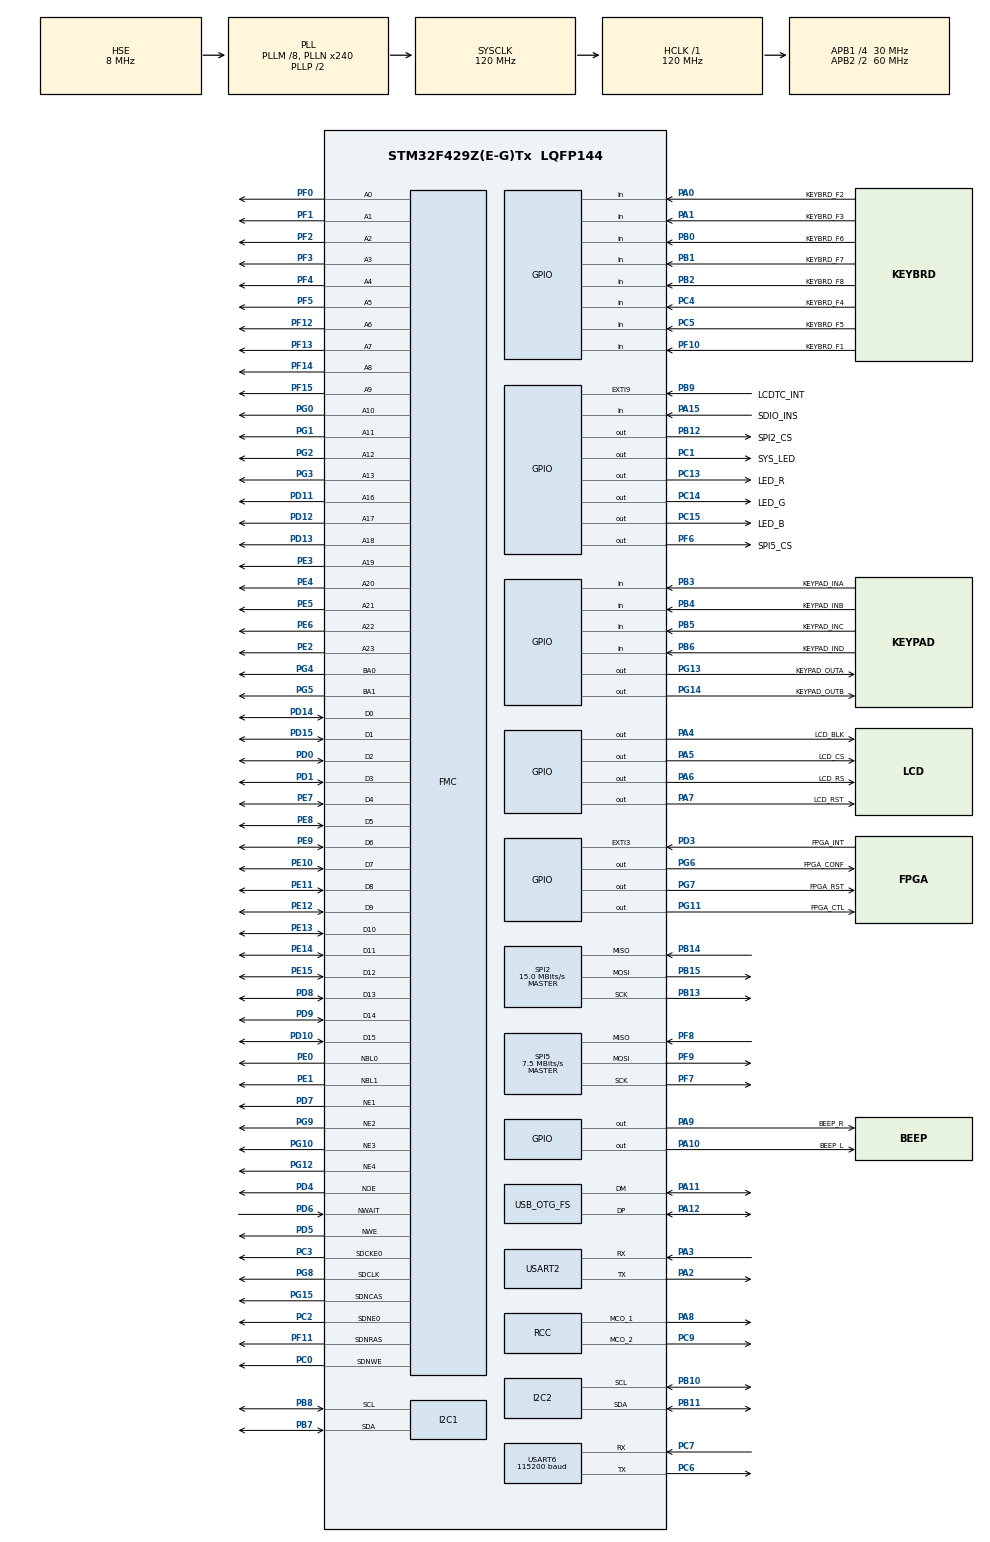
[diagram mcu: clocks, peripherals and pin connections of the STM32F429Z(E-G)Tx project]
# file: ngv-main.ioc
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FATFS._CODE_PAGE=850
FATFS._MAX_SS=4096
FATFS._MIN_SS=4096
FATFS._USE_LFN=1
FMC.AddressSetupTime1=0
FMC.AddressSetupTime2=0
FMC.AddressSetupTime3=0
FMC.AddressSetupTime4=0
FMC.BusTurnAroundDuration1=0
FMC.BusTurnAroundDuration2=0
FMC.BusTurnAroundDuration3=0
FMC.BusTurnAroundDuration4=0
FMC.CASLatency1=FMC_SDRAM_CAS_LATENCY_2
FMC.ColumnBitsNumber1=FMC_SDRAM_COLUMN_BITS_NUM_9
FMC.DataSetupTime1=1
FMC.DataSetupTime2=1
FMC.DataSetupTime3=1
FMC.DataSetupTime4=1
FMC.ExitSelfRefreshDelay1=5
FMC.LoadToActiveDelay1=2
FMC.RCDDelay1=2
FMC.RPDelay1=2
FMC.RPDelay2=2
FMC.ReadPipeDelay1=FMC_SDRAM_RPIPE_DELAY_1
FMC.ReadPipeDelay2=FMC_SDRAM_RPIPE_DELAY_1
FMC.RowCycleDelay1=5
FMC.RowCycleDelay2=5
FMC.SDClockPeriod1=FMC_SDRAM_CLOCK_PERIOD_2
FMC.SDClockPeriod2=FMC_SDRAM_CLOCK_PERIOD_2
FMC.SelfRefreshTime1=4
FMC.WriteRecoveryTime1=2
Mcu.Family=STM32F4
Mcu.Name=STM32F429Z(E-G)Tx
Mcu.Package=LQFP144
NVIC.EXTI3_IRQn=true\:0\:0\:false\:false\:true\:true
NVIC.EXTI9_5_IRQn=true\:0\:0\:false\:false\:true\:true
NVIC.OTG_FS_IRQn=true\:0\:0\:false\:false\:true\:false
NVIC.PriorityGroup=NVIC_PRIORITYGROUP_4
NVIC.TIM1_UP_TIM10_IRQn=true\:0\:0\:false\:false\:true\:true
PA0/WKUP.GPIO_Label=KEYBRD_F2
PA0/WKUP.GPIO_PuPd=GPIO_PULLUP
PA0/WKUP.Signal=GPIO_Input
PA1.GPIO_Label=KEYBRD_F3
PA1.GPIO_Mode=GPIO_MODE_INPUT
PA1.GPIO_PuPd=GPIO_PULLUP
PA1.Signal=GPIO_Input
PA10.GPIO_Label=BEEP_L
PA10.GPIO_Speed=GPIO_SPEED_FREQ_VERY_HIGH
PA10.Signal=GPIO_Output
PA11.Mode=Device_Only
PA11.Signal=USB_OTG_FS_DM
PA12.Mode=Device_Only
PA12.Signal=USB_OTG_FS_DP
PA13.Mode=Serial_Wire
PA13.Signal=SYS_JTMS-SWDIO
PA14.Mode=Serial_Wire
PA14.Signal=SYS_JTCK-SWCLK
PA15.GPIO_Label=SDIO_INS
PA15.GPIO_PuPd=GPIO_PULLUP
PA15.Signal=GPIO_Input
PA2.Mode=Asynchronous
PA2.Signal=USART2_TX
PA3.Mode=Asynchronous
PA3.Signal=USART2_RX
PA4.GPIO_Label=LCD_BLK
PA4.GPIO_Speed=GPIO_SPEED_FREQ_VERY_HIGH
PA4.Signal=GPIO_Output
PA5.GPIO_Label=LCD_CS
PA5.GPIO_Speed=GPIO_SPEED_FREQ_VERY_HIGH
PA5.PinState=GPIO_PIN_SET
PA5.Signal=GPIO_Output
PA6.GPIO_Label=LCD_RS
PA6.GPIO_Speed=GPIO_SPEED_FREQ_VERY_HIGH
PA6.Signal=GPIO_Output
PA7.GPIO_Label=LCD_RST
PA7.GPIO_Speed=GPIO_SPEED_FREQ_VERY_HIGH
PA7.PinState=GPIO_PIN_SET
PA7.Signal=GPIO_Output
PA8.Mode=Clock-out-1
PA8.Signal=RCC_MCO_1
PA9.GPIO_Label=BEEP_R
PA9.GPIO_Speed=GPIO_SPEED_FREQ_VERY_HIGH
PA9.Signal=GPIO_Output
PB0.GPIO_Label=KEYBRD_F6
PB0.GPIO_Mode=GPIO_MODE_INPUT
PB0.GPIO_PuPd=GPIO_PULLUP
PB0.Signal=GPIO_Input
PB1.GPIO_Label=KEYBRD_F7
PB1.GPIO_Mode=GPIO_MODE_INPUT
PB1.GPIO_PuPd=GPIO_PULLUP
PB1.Signal=GPIO_Input
PB10.Mode=I2C
PB10.Signal=I2C2_SCL
PB11.Mode=I2C
PB11.Signal=I2C2_SDA
PB12.GPIO_Label=SPI2_CS
PB12.GPIO_Speed=GPIO_SPEED_FREQ_VERY_HIGH
PB12.PinState=GPIO_PIN_SET
PB12.Signal=GPIO_Output
PB13.Mode=Full_Duplex_Master
PB13.Signal=SPI2_SCK
PB14.Mode=Full_Duplex_Master
PB14.Signal=SPI2_MISO
PB15.Mode=Full_Duplex_Master
PB15.Signal=SPI2_MOSI
PB2/BOOT1.GPIO_Label=KEYBRD_F8
PB2/BOOT1.GPIO_Mode=GPIO_MODE_INPUT
PB2/BOOT1.GPIO_PuPd=GPIO_PULLUP
PB2/BOOT1.Signal=GPIO_Input
PB3.GPIO_Label=KEYPAD_INA
PB3.GPIO_Mode=GPIO_MODE_INPUT
PB3.GPIO_PuPd=GPIO_PULLUP
PB3.Signal=GPIO_Input
PB4.GPIO_Label=KEYPAD_INB
PB4.GPIO_Mode=GPIO_MODE_INPUT
PB4.GPIO_PuPd=GPIO_PULLUP
PB4.Signal=GPIO_Input
PB5.GPIO_Label=KEYPAD_INC
PB5.GPIO_Mode=GPIO_MODE_INPUT
PB5.GPIO_PuPd=GPIO_PULLUP
PB5.Signal=GPIO_Input
PB6.GPIO_Label=KEYPAD_IND
PB6.GPIO_Mode=GPIO_MODE_INPUT
PB6.GPIO_PuPd=GPIO_PULLUP
PB6.Signal=GPIO_Input
PB7.Mode=I2C
PB7.Signal=I2C1_SDA
PB8.Mode=I2C
PB8.Signal=I2C1_SCL
PB9.GPIO_Label=LCDTC_INT
PB9.GPIO_PuPd=GPIO_PULLUP
PB9.Signal=GPXTI9
PC0.Signal=FMC_SDNWE
PC1.GPIO_Label=SYS_LED
PC1.GPIO_Speed=GPIO_SPEED_FREQ_VERY_HIGH
PC1.PinState=GPIO_PIN_SET
PC1.Signal=GPIO_Output
PC10.Signal=SDIO_D2
PC11.Signal=SDIO_D3
PC12.Signal=SDIO_CK
PC13.GPIO_Label=LED_R
PC13.Signal=GPIO_Output
PC14/OSC32_IN.GPIO_Label=LED_G
PC14/OSC32_IN.Signal=GPIO_Output
PC15/OSC32_OUT.GPIO_Label=LED_B
PC15/OSC32_OUT.Signal=GPIO_Output
PC2.Mode=SdramChipSelect1_1
PC2.Signal=FMC_SDNE0
PC3.Mode=SdramChipSelect1_1
PC3.Signal=FMC_SDCKE0
PC4.GPIO_Label=KEYBRD_F4
PC4.GPIO_Mode=GPIO_MODE_INPUT
PC4.GPIO_PuPd=GPIO_PULLUP
PC4.Signal=GPIO_Input
PC5.GPIO_Label=KEYBRD_F5
PC5.GPIO_Mode=GPIO_MODE_INPUT
PC5.GPIO_PuPd=GPIO_PULLUP
PC5.Signal=GPIO_Input
PC6.Mode=Asynchronous
PC6.Signal=USART6_TX
PC7.Mode=Asynchronous
PC7.Signal=USART6_RX
PC8.Signal=SDIO_D0
PC9.Mode=Clock-out-2
PC9.Signal=RCC_MCO_2
PD0.Signal=FMC_D2_DA2
PD1.Signal=FMC_D3_DA3
PD10.Signal=FMC_D15_DA15
PD11.Signal=FMC_A16_CLE
PD12.Signal=FMC_A17_ALE
PD13.Signal=FMC_A18
PD14.Signal=FMC_D0_DA0
PD15.Signal=FMC_D1_DA1
PD2.Signal=SDIO_CMD
PD3.GPIO_Label=FPGA_INT
PD3.GPIO_PuPd=GPIO_PULLUP
PD3.Signal=GPXTI3
PD4.Signal=FMC_NOE
PD5.Signal=FMC_NWE
PD6.Signal=FMC_NWAIT
PD7.Mode=NorPsramChipSelect1_1
PD7.Signal=FMC_NE1
PD8.Signal=FMC_D13_DA13
PD9.Signal=FMC_D14_DA14
PE0.Signal=FMC_NBL0
PE1.Signal=FMC_NBL1
PE10.Signal=FMC_D7_DA7
PE11.Signal=FMC_D8_DA8
PE12.Signal=FMC_D9_DA9
PE13.Signal=FMC_D10_DA10
PE14.Signal=FMC_D11_DA11
PE15.Signal=FMC_D12_DA12
PE2.Signal=FMC_A23
PE3.Signal=FMC_A19
PE4.Signal=FMC_A20
PE5.Signal=FMC_A21
PE6.Signal=FMC_A22
PE7.Signal=FMC_D4_DA4
PE8.Signal=FMC_D5_DA5
PE9.Signal=FMC_D6_DA6
PF0.Signal=FMC_A0
PF1.Signal=FMC_A1
PF10.GPIO_Label=KEYBRD_F1
PF10.GPIO_PuPd=GPIO_PULLUP
PF10.Signal=GPIO_Input
PF11.Signal=FMC_SDNRAS
PF12.Signal=FMC_A6
PF13.Signal=FMC_A7
PF14.Signal=FMC_A8
PF15.Signal=FMC_A9
PF2.Signal=FMC_A2
PF3.Signal=FMC_A3
PF4.Signal=FMC_A4
PF5.Signal=FMC_A5
PF6.GPIO_Label=SPI5_CS
PF6.GPIO_Speed=GPIO_SPEED_FREQ_VERY_HIGH
PF6.PinState=GPIO_PIN_SET
PF6.Signal=GPIO_Output
PF7.Mode=Full_Duplex_Master
PF7.Signal=SPI5_SCK
PF8.Mode=Full_Duplex_Master
PF8.Signal=SPI5_MISO
PF9.Mode=Full_Duplex_Master
PF9.Signal=SPI5_MOSI
PG0.Signal=FMC_A10
PG1.Signal=FMC_A11
PG10.Mode=NorPsramChipSelect3_3
PG10.Signal=FMC_NE3
PG11.GPIO_Label=FPGA_CTL
PG11.GPIO_ModeDefaultOutputPP=GPIO_MODE_OUTPUT_OD
PG11.GPIO_PuPd=GPIO_PULLUP
PG11.GPIO_Speed=GPIO_SPEED_FREQ_VERY_HIGH
PG11.PinState=GPIO_PIN_SET
PG11.Signal=GPIO_Output
PG12.Mode=NorPsramChipSelect4_4
PG12.Signal=FMC_NE4
PG13.GPIO_Label=KEYPAD_OUTA
PG13.GPIO_ModeDefaultOutputPP=GPIO_MODE_OUTPUT_PP
PG13.GPIO_Speed=GPIO_SPEED_FREQ_VERY_HIGH
PG13.PinState=GPIO_PIN_SET
PG13.Signal=GPIO_Output
PG14.GPIO_Label=KEYPAD_OUTB
PG14.GPIO_ModeDefaultOutputPP=GPIO_MODE_OUTPUT_PP
PG14.GPIO_Speed=GPIO_SPEED_FREQ_VERY_HIGH
PG14.PinState=GPIO_PIN_SET
PG14.Signal=GPIO_Output
PG15.Signal=FMC_SDNCAS
PG2.Signal=FMC_A12
PG3.Signal=FMC_A13
PG4.Signal=FMC_A14_BA0
PG5.Signal=FMC_A15_BA1
PG6.GPIO_Label=FPGA_CONF
PG6.GPIO_ModeDefaultOutputPP=GPIO_MODE_OUTPUT_OD
PG6.GPIO_PuPd=GPIO_NOPULL
PG6.GPIO_Speed=GPIO_SPEED_FREQ_VERY_HIGH
PG6.PinState=GPIO_PIN_SET
PG6.Signal=GPIO_Output
PG7.GPIO_Label=FPGA_RST
PG7.GPIO_ModeDefaultOutputPP=GPIO_MODE_OUTPUT_OD
PG7.GPIO_PuPd=GPIO_PULLUP
PG7.GPIO_Speed=GPIO_SPEED_FREQ_VERY_HIGH
PG7.PinState=GPIO_PIN_SET
PG7.Signal=GPIO_Output
PG8.Signal=FMC_SDCLK
PG9.Mode=NorPsramChipSelect2_2
PG9.Signal=FMC_NE2
PH0/OSC_IN.Mode=HSE-External-Oscillator
PH0/OSC_IN.Signal=RCC_OSC_IN
PH1/OSC_OUT.Mode=HSE-External-Oscillator
PH1/OSC_OUT.Signal=RCC_OSC_OUT
ProjectManager.HeapSize=0x1000
ProjectManager.StackSize=0x2000
ProjectManager.TargetToolchain=SW4STM32
RCC.48MHZClocksFreq_Value=48000000
RCC.AHBFreq_Value=120000000
RCC.APB1CLKDivider=RCC_HCLK_DIV4
RCC.APB1Freq_Value=30000000
RCC.APB1TimFreq_Value=60000000
RCC.APB2CLKDivider=RCC_HCLK_DIV2
RCC.APB2Freq_Value=60000000
RCC.APB2TimFreq_Value=120000000
RCC.CortexFreq_Value=120000000
RCC.HCLKFreq_Value=120000000
RCC.HSE_VALUE=8000000
RCC.HSI_VALUE=16000000
RCC.LSE_VALUE=32768
RCC.PLLI2SN=120
RCC.PLLM=8
RCC.PLLN=240
RCC.PLLQ=5
RCC.RCC_MCO1Source=RCC_MCO1SOURCE_PLLCLK
RCC.RCC_MCO2Source=RCC_MCO2SOURCE_PLLI2SCLK
RCC.RCC_MCODiv1=RCC_MCODIV_5
RCC.RCC_MCODiv2=RCC_MCODIV_5
RCC.SYSCLKFreq_VALUE=120000000
RCC.SYSCLKSource=RCC_SYSCLKSOURCE_PLLCLK
RCC.VCOOutputFreq_Value=240000000
SH.FMC_A0.0=FMC_A0,13b-sda1
SH.FMC_A0.1=FMC_A0,24b-a1
SH.FMC_A0.2=FMC_A0,24b-a2
SH.FMC_A0.3=FMC_A0,24b-a3
SH.FMC_A0.4=FMC_A0,24b-a4
SH.FMC_A1.0=FMC_A1,13b-sda1
SH.FMC_A1.1=FMC_A1,24b-a1
SH.FMC_A1.2=FMC_A1,24b-a2
SH.FMC_A1.3=FMC_A1,24b-a3
SH.FMC_A1.4=FMC_A1,24b-a4
SH.FMC_A10.0=FMC_A10,13b-sda1
SH.FMC_A10.1=FMC_A10,24b-a1
SH.FMC_A10.2=FMC_A10,24b-a2
SH.FMC_A10.3=FMC_A10,24b-a3
SH.FMC_A10.4=FMC_A10,24b-a4
SH.FMC_A11.0=FMC_A11,13b-sda1
SH.FMC_A11.1=FMC_A11,24b-a1
SH.FMC_A11.2=FMC_A11,24b-a2
SH.FMC_A11.3=FMC_A11,24b-a3
SH.FMC_A11.4=FMC_A11,24b-a4
SH.FMC_A12.0=FMC_A12,13b-sda1
SH.FMC_A12.1=FMC_A12,24b-a1
SH.FMC_A12.2=FMC_A12,24b-a2
SH.FMC_A12.3=FMC_A12,24b-a3
SH.FMC_A12.4=FMC_A12,24b-a4
SH.FMC_A13.0=FMC_A13,24b-a1
SH.FMC_A13.1=FMC_A13,24b-a2
SH.FMC_A13.2=FMC_A13,24b-a3
SH.FMC_A13.3=FMC_A13,24b-a4
SH.FMC_A14_BA0.0=FMC_BA0,FourSdramBanks1
SH.FMC_A14_BA0.1=FMC_A14,24b-a1
SH.FMC_A14_BA0.2=FMC_A14,24b-a2
SH.FMC_A14_BA0.3=FMC_A14,24b-a3
SH.FMC_A14_BA0.4=FMC_A14,24b-a4
SH.FMC_A15_BA1.0=FMC_BA1,FourSdramBanks1
SH.FMC_A15_BA1.1=FMC_A15,24b-a1
SH.FMC_A15_BA1.2=FMC_A15,24b-a2
SH.FMC_A15_BA1.3=FMC_A15,24b-a3
SH.FMC_A15_BA1.4=FMC_A15,24b-a4
SH.FMC_A16_CLE.0=FMC_A16,24b-a1
SH.FMC_A16_CLE.1=FMC_A16,24b-a2
SH.FMC_A16_CLE.2=FMC_A16,24b-a3
SH.FMC_A16_CLE.3=FMC_A16,24b-a4
SH.FMC_A17_ALE.0=FMC_A17,24b-a1
SH.FMC_A17_ALE.1=FMC_A17,24b-a2
SH.FMC_A17_ALE.2=FMC_A17,24b-a3
SH.FMC_A17_ALE.3=FMC_A17,24b-a4
SH.FMC_A18.0=FMC_A18,24b-a1
SH.FMC_A18.1=FMC_A18,24b-a2
SH.FMC_A18.2=FMC_A18,24b-a3
SH.FMC_A18.3=FMC_A18,24b-a4
SH.FMC_A19.0=FMC_A19,24b-a1
SH.FMC_A19.1=FMC_A19,24b-a2
SH.FMC_A19.2=FMC_A19,24b-a3
SH.FMC_A19.3=FMC_A19,24b-a4
SH.FMC_A2.0=FMC_A2,13b-sda1
SH.FMC_A2.1=FMC_A2,24b-a1
SH.FMC_A2.2=FMC_A2,24b-a2
SH.FMC_A2.3=FMC_A2,24b-a3
SH.FMC_A2.4=FMC_A2,24b-a4
SH.FMC_A20.0=FMC_A20,24b-a1
SH.FMC_A20.1=FMC_A20,24b-a2
SH.FMC_A20.2=FMC_A20,24b-a3
SH.FMC_A20.3=FMC_A20,24b-a4
SH.FMC_A21.0=FMC_A21,24b-a1
SH.FMC_A21.1=FMC_A21,24b-a2
SH.FMC_A21.2=FMC_A21,24b-a3
SH.FMC_A21.3=FMC_A21,24b-a4
SH.FMC_A22.0=FMC_A22,24b-a1
SH.FMC_A22.1=FMC_A22,24b-a2
SH.FMC_A22.2=FMC_A22,24b-a3
SH.FMC_A22.3=FMC_A22,24b-a4
SH.FMC_A23.0=FMC_A23,24b-a1
SH.FMC_A23.1=FMC_A23,24b-a2
SH.FMC_A23.2=FMC_A23,24b-a3
SH.FMC_A23.3=FMC_A23,24b-a4
SH.FMC_A3.0=FMC_A3,13b-sda1
SH.FMC_A3.1=FMC_A3,24b-a1
SH.FMC_A3.2=FMC_A3,24b-a2
SH.FMC_A3.3=FMC_A3,24b-a3
SH.FMC_A3.4=FMC_A3,24b-a4
SH.FMC_A4.0=FMC_A4,13b-sda1
SH.FMC_A4.1=FMC_A4,24b-a1
SH.FMC_A4.2=FMC_A4,24b-a2
SH.FMC_A4.3=FMC_A4,24b-a3
SH.FMC_A4.4=FMC_A4,24b-a4
SH.FMC_A5.0=FMC_A5,13b-sda1
SH.FMC_A5.1=FMC_A5,24b-a1
SH.FMC_A5.2=FMC_A5,24b-a2
SH.FMC_A5.3=FMC_A5,24b-a3
SH.FMC_A5.4=FMC_A5,24b-a4
SH.FMC_A6.0=FMC_A6,13b-sda1
SH.FMC_A6.1=FMC_A6,24b-a1
SH.FMC_A6.2=FMC_A6,24b-a2
SH.FMC_A6.3=FMC_A6,24b-a3
SH.FMC_A6.4=FMC_A6,24b-a4
SH.FMC_A7.0=FMC_A7,13b-sda1
SH.FMC_A7.1=FMC_A7,24b-a1
SH.FMC_A7.2=FMC_A7,24b-a2
SH.FMC_A7.3=FMC_A7,24b-a3
SH.FMC_A7.4=FMC_A7,24b-a4
SH.FMC_A8.0=FMC_A8,13b-sda1
SH.FMC_A8.1=FMC_A8,24b-a1
SH.FMC_A8.2=FMC_A8,24b-a2
SH.FMC_A8.3=FMC_A8,24b-a3
SH.FMC_A8.4=FMC_A8,24b-a4
SH.FMC_A9.0=FMC_A9,13b-sda1
SH.FMC_A9.1=FMC_A9,24b-a1
SH.FMC_A9.2=FMC_A9,24b-a2
SH.FMC_A9.3=FMC_A9,24b-a3
SH.FMC_A9.4=FMC_A9,24b-a4
SH.FMC_D0_DA0.0=FMC_D0,sd-16b-d1
SH.FMC_D0_DA0.1=FMC_D0,8b-d2
SH.FMC_D0_DA0.2=FMC_D0,8b-d3
SH.FMC_D0_DA0.3=FMC_D0,8b-d4
SH.FMC_D0_DA0.4=FMC_D0,8b-d1
SH.FMC_D10_DA10.0=FMC_D10,sd-16b-d1
SH.FMC_D11_DA11.0=FMC_D11,sd-16b-d1
SH.FMC_D12_DA12.0=FMC_D12,sd-16b-d1
SH.FMC_D13_DA13.0=FMC_D13,sd-16b-d1
SH.FMC_D14_DA14.0=FMC_D14,sd-16b-d1
SH.FMC_D15_DA15.0=FMC_D15,sd-16b-d1
SH.FMC_D1_DA1.0=FMC_D1,sd-16b-d1
SH.FMC_D1_DA1.1=FMC_D1,8b-d2
SH.FMC_D1_DA1.2=FMC_D1,8b-d3
SH.FMC_D1_DA1.3=FMC_D1,8b-d4
SH.FMC_D1_DA1.4=FMC_D1,8b-d1
SH.FMC_D2_DA2.0=FMC_D2,sd-16b-d1
SH.FMC_D2_DA2.1=FMC_D2,8b-d2
SH.FMC_D2_DA2.2=FMC_D2,8b-d3
SH.FMC_D2_DA2.3=FMC_D2,8b-d4
SH.FMC_D2_DA2.4=FMC_D2,8b-d1
SH.FMC_D3_DA3.0=FMC_D3,sd-16b-d1
SH.FMC_D3_DA3.1=FMC_D3,8b-d2
SH.FMC_D3_DA3.2=FMC_D3,8b-d3
SH.FMC_D3_DA3.3=FMC_D3,8b-d4
SH.FMC_D3_DA3.4=FMC_D3,8b-d1
SH.FMC_D4_DA4.0=FMC_D4,sd-16b-d1
SH.FMC_D4_DA4.1=FMC_D4,8b-d2
SH.FMC_D4_DA4.2=FMC_D4,8b-d3
SH.FMC_D4_DA4.3=FMC_D4,8b-d4
SH.FMC_D4_DA4.4=FMC_D4,8b-d1
SH.FMC_D5_DA5.0=FMC_D5,sd-16b-d1
SH.FMC_D5_DA5.1=FMC_D5,8b-d2
SH.FMC_D5_DA5.2=FMC_D5,8b-d3
SH.FMC_D5_DA5.3=FMC_D5,8b-d4
SH.FMC_D5_DA5.4=FMC_D5,8b-d1
SH.FMC_D6_DA6.0=FMC_D6,sd-16b-d1
SH.FMC_D6_DA6.1=FMC_D6,8b-d2
SH.FMC_D6_DA6.2=FMC_D6,8b-d3
SH.FMC_D6_DA6.3=FMC_D6,8b-d4
SH.FMC_D6_DA6.4=FMC_D6,8b-d1
SH.FMC_D7_DA7.0=FMC_D7,sd-16b-d1
SH.FMC_D7_DA7.1=FMC_D7,8b-d2
SH.FMC_D7_DA7.2=FMC_D7,8b-d3
SH.FMC_D7_DA7.3=FMC_D7,8b-d4
SH.FMC_D7_DA7.4=FMC_D7,8b-d1
SH.FMC_D8_DA8.0=FMC_D8,sd-16b-d1
SH.FMC_D9_DA9.0=FMC_D9,sd-16b-d1
SH.FMC_NBL0.0=FMC_NBL0,Sd2ByteEnable1
SH.FMC_NBL1.0=FMC_NBL1,Sd2ByteEnable1
SH.FMC_NOE.0=FMC_NOE,Sram1
SH.FMC_NOE.1=FMC_NOE,Sram2
SH.FMC_NOE.2=FMC_NOE,Sram3
SH.FMC_NOE.3=FMC_NOE,Sram4
SH.FMC_NWAIT.0=FMC_NWAIT,AsynchronousWait2
SH.FMC_NWAIT.1=FMC_NWAIT,AsynchronousWait3
SH.FMC_NWAIT.2=FMC_NWAIT,AsynchronousWait4
SH.FMC_NWE.0=FMC_NWE,Sram1
SH.FMC_NWE.1=FMC_NWE,Sram2
SH.FMC_NWE.2=FMC_NWE,Sram3
SH.FMC_NWE.3=FMC_NWE,Sram4
SH.FMC_SDCLK.0=FMC_SDCLK,13b-sda1
SH.FMC_SDNCAS.0=FMC_SDNCAS,13b-sda1
SH.FMC_SDNRAS.0=FMC_SDNRAS,13b-sda1
SH.FMC_SDNWE.0=FMC_SDNWE,13b-sda1
SPI2.BaudRatePrescaler=SPI_BAUDRATEPRESCALER_2
SPI2.CalculateBaudRate=15.0 MBits/s
SPI2.Direction=SPI_DIRECTION_2LINES
SPI2.Mode=SPI_MODE_MASTER
SPI2.VirtualType=VM_MASTER
SPI5.BaudRatePrescaler=SPI_BAUDRATEPRESCALER_8
SPI5.CalculateBaudRate=7.5 MBits/s
SPI5.Direction=SPI_DIRECTION_2LINES
SPI5.Mode=SPI_MODE_MASTER
SPI5.VirtualType=VM_MASTER
TIM10.Period=239
TIM10.Prescaler=5
USART2.VirtualMode=VM_ASYNC
USART6.BaudRate=115200
USART6.VirtualMode=VM_ASYNC
USB_DEVICE.CLASS_NAME_FS=MSC
USB_DEVICE.CONFIGURATION_STRING_MSC_FS=NGV Config
USB_DEVICE.INTERFACE_STRING_MSC_FS=NGV Interface
USB_DEVICE.MANUFACTURER_STRING-MSC_FS=NSDN
USB_DEVICE.MSC_MEDIA_PACKET-MSC_FS=8192
USB_DEVICE.PRODUCT_STRING_MSC_FS=NyaGame Vita v1.0
USB_DEVICE.VirtualMode-MSC_FS=Msc
USB_DEVICE.VirtualModeFS=Msc_FS
USB_OTG_FS.VirtualMode=Device_Only
VP_FATFS_VS_Generic.Mode=User_defined
VP_TIM10_VS_ClockSourceINT.Mode=Enable_Timer
VP_USB_DEVICE_VS_USB_DEVICE_MSC_FS.Mode=MSC_FS
board=ngv-main

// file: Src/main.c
/**
  ******************************************************************************
  * @file           : main.c
  * @brief          : Main program body
  ******************************************************************************
  * This notice applies to any and all portions of this file
  * that are not between comment pairs USER CODE BEGIN and
  * USER CODE END. Other portions of this file, whether
  * inserted by the user or by software development tools
  * are owned by their respective copyright owners.
  *
  * Copyright (c) 2018 STMicroelectronics International N.V.
  * All rights reserved.
  *
  * Redistribution and use in source and binary forms, with or without
  * modification, are permitted, provided that the following conditions are met:
  *
  * 1. Redistribution of source code must retain the above copyright notice,
  *    this list of conditions and the following disclaimer.
  * 2. Redistributions in binary form must reproduce the above copyright notice,
  *    this list of conditions and the following disclaimer in the documentation
  *    and/or other materials provided with the distribution.
  * 3. Neither the name of STMicroelectronics nor the names of other
  *    contributors to this software may be used to endorse or promote products
  *    derived from this software without specific written permission.
  * 4. This software, including modifications and/or derivative works of this
  *    software, must execute solely and exclusively on microcontroller or
  *    microprocessor devices manufactured by or for STMicroelectronics.
  * 5. Redistribution and use of this software other than as permitted under
  *    this license is void and will automatically terminate your rights under
  *    this license.
  *
  * THIS SOFTWARE IS PROVIDED BY STMICROELECTRONICS AND CONTRIBUTORS "AS IS"
  * AND ANY EXPRESS, IMPLIED OR STATUTORY WARRANTIES, INCLUDING, BUT NOT
  * LIMITED TO, THE IMPLIED WARRANTIES OF MERCHANTABILITY, FITNESS FOR A
  * PARTICULAR PURPOSE AND NON-INFRINGEMENT OF THIRD PARTY INTELLECTUAL PROPERTY
  * RIGHTS ARE DISCLAIMED TO THE FULLEST EXTENT PERMITTED BY LAW. IN NO EVENT
  * SHALL STMICROELECTRONICS OR CONTRIBUTORS BE LIABLE FOR ANY DIRECT, INDIRECT,
  * INCIDENTAL, SPECIAL, EXEMPLARY, OR CONSEQUENTIAL DAMAGES (INCLUDING, BUT NOT
  * LIMITED TO, PROCUREMENT OF SUBSTITUTE GOODS OR SERVICES; LOSS OF USE, DATA,
  * OR PROFITS; OR BUSINESS INTERRUPTION) HOWEVER CAUSED AND ON ANY THEORY OF
  * LIABILITY, WHETHER IN CONTRACT, STRICT LIABILITY, OR TORT (INCLUDING
  * NEGLIGENCE OR OTHERWISE) ARISING IN ANY WAY OUT OF THE USE OF THIS SOFTWARE,
  * EVEN IF ADVISED OF THE POSSIBILITY OF SUCH DAMAGE.
  *
  ******************************************************************************
  */
#include "main.h"
#include "stm32f4xx_hal.h"
#include "fatfs.h"
#include "usb_device.h"

/* USER CODE BEGIN Includes */
#include "ngv_bios.h"
#include "ngp_bios.h"
#include "flash.h"
#include "dram.h"
/* USER CODE END Includes */

I2C_HandleTypeDef hi2c1;
I2C_HandleTypeDef hi2c2;

SPI_HandleTypeDef hspi2;
SPI_HandleTypeDef hspi5;

TIM_HandleTypeDef htim10;

UART_HandleTypeDef huart2;
UART_HandleTypeDef huart6;

SRAM_HandleTypeDef hsram1;
SRAM_HandleTypeDef hsram2;
SRAM_HandleTypeDef hsram3;
SRAM_HandleTypeDef hsram4;
SDRAM_HandleTypeDef hsdram1;

/* USER CODE BEGIN PV */
/* Private variables ---------------------------------------------------------*/
extern Flash* flash;
/* USER CODE END PV */

void SystemClock_Config(void);
static void MX_GPIO_Init(void);
static void MX_FMC_Init(void);
static void MX_I2C1_Init(void);
static void MX_SPI2_Init(void);
static void MX_I2C2_Init(void);
static void MX_USART2_UART_Init(void);
static void MX_USART6_UART_Init(void);
static void MX_SPI5_Init(void);
static void MX_TIM10_Init(void);

/* USER CODE BEGIN PFP */
/* Private function prototypes -----------------------------------------------*/
void tick() {
	HAL_GPIO_TogglePin(SYS_LED_GPIO_Port, SYS_LED_Pin);
}

void _lcd_ctl_blk(unsigned char state) {
	HAL_GPIO_WritePin(LCD_BLK_GPIO_Port, LCD_BLK_Pin, state);
}
void _lcd_ctl_cs(unsigned char state) {
	HAL_GPIO_WritePin(LCD_CS_GPIO_Port, LCD_CS_Pin, state);
}
void _lcd_ctl_rs(unsigned char state) {
	HAL_GPIO_WritePin(LCD_RS_GPIO_Port, LCD_RS_Pin, state);
}
void _lcd_ctl_rst(unsigned char state) {
	HAL_GPIO_WritePin(LCD_RST_GPIO_Port, LCD_RST_Pin, state);
}
/* USER CODE END PFP */

int main(void)
{

  /* MCU Configuration----------------------------------------------------------*/

  /* Reset of all peripherals, Initializes the Flash interface and the Systick. */
  HAL_Init();

  /* Configure the system clock */
  SystemClock_Config();

  /* Initialize all configured peripherals */
  MX_GPIO_Init();
  MX_FMC_Init();
  MX_I2C1_Init();
  MX_SPI2_Init();
  MX_I2C2_Init();
  MX_USART2_UART_Init();
  MX_USART6_UART_Init();
  MX_SPI5_Init();
  MX_USB_DEVICE_Init();
  MX_FATFS_Init();
  MX_TIM10_Init();
  /* USER CODE BEGIN 2 */
  SDRAM_Init(&hsdram1);

  flash = FlashInit(&hspi5, SPI5_CS_GPIO_Port, SPI5_CS_Pin, W25Q128);
  ngv_setup();
  /* USER CODE END 2 */

  /* Infinite loop */
  /* USER CODE BEGIN WHILE */
  while (1) ngp_loop();
  /* USER CODE END WHILE */

}

void SystemClock_Config(void)
{

  RCC_OscInitTypeDef RCC_OscInitStruct;
  RCC_ClkInitTypeDef RCC_ClkInitStruct;
  RCC_PeriphCLKInitTypeDef PeriphClkInitStruct;

    /**Configure the main internal regulator output voltage
    */
  __HAL_RCC_PWR_CLK_ENABLE();

  __HAL_PWR_VOLTAGESCALING_CONFIG(PWR_REGULATOR_VOLTAGE_SCALE3);

    /**Initializes the CPU, AHB and APB busses clocks
    */
  RCC_OscInitStruct.OscillatorType = RCC_OSCILLATORTYPE_HSE;
  RCC_OscInitStruct.HSEState = RCC_HSE_ON;
  RCC_OscInitStruct.PLL.PLLState = RCC_PLL_ON;
  RCC_OscInitStruct.PLL.PLLSource = RCC_PLLSOURCE_HSE;
  RCC_OscInitStruct.PLL.PLLM = 8;
  RCC_OscInitStruct.PLL.PLLN = 240;
  RCC_OscInitStruct.PLL.PLLP = RCC_PLLP_DIV2;
  RCC_OscInitStruct.PLL.PLLQ = 5;
  if (HAL_RCC_OscConfig(&RCC_OscInitStruct) != HAL_OK)
  {
    _Error_Handler(__FILE__, __LINE__);
  }

    /**Initializes the CPU, AHB and APB busses clocks
    */
  RCC_ClkInitStruct.ClockType = RCC_CLOCKTYPE_HCLK|RCC_CLOCKTYPE_SYSCLK
                              |RCC_CLOCKTYPE_PCLK1|RCC_CLOCKTYPE_PCLK2;
  RCC_ClkInitStruct.SYSCLKSource = RCC_SYSCLKSOURCE_PLLCLK;
  RCC_ClkInitStruct.AHBCLKDivider = RCC_SYSCLK_DIV1;
  RCC_ClkInitStruct.APB1CLKDivider = RCC_HCLK_DIV4;
  RCC_ClkInitStruct.APB2CLKDivider = RCC_HCLK_DIV2;

  if (HAL_RCC_ClockConfig(&RCC_ClkInitStruct, FLASH_LATENCY_3) != HAL_OK)
  {
    _Error_Handler(__FILE__, __LINE__);
  }

  PeriphClkInitStruct.PeriphClockSelection = RCC_PERIPHCLK_PLLI2S;
  PeriphClkInitStruct.PLLI2S.PLLI2SN = 120;
  PeriphClkInitStruct.PLLI2S.PLLI2SR = 2;
  if (HAL_RCCEx_PeriphCLKConfig(&PeriphClkInitStruct) != HAL_OK)
  {
    _Error_Handler(__FILE__, __LINE__);
  }

  HAL_RCC_MCOConfig(RCC_MCO1, RCC_MCO1SOURCE_PLLCLK, RCC_MCODIV_5);

  HAL_RCC_MCOConfig(RCC_MCO2, RCC_MCO2SOURCE_PLLI2SCLK, RCC_MCODIV_5);

    /**Configure the Systick interrupt time
    */
  HAL_SYSTICK_Config(HAL_RCC_GetHCLKFreq()/1000);

    /**Configure the Systick
    */
  HAL_SYSTICK_CLKSourceConfig(SYSTICK_CLKSOURCE_HCLK);

  /* SysTick_IRQn interrupt configuration */
  HAL_NVIC_SetPriority(SysTick_IRQn, 0, 0);
}

/* I2C1 init function */
static void MX_I2C1_Init(void)
{

  hi2c1.Instance = I2C1;
  hi2c1.Init.ClockSpeed = 100000;
  hi2c1.Init.DutyCycle = I2C_DUTYCYCLE_2;
  hi2c1.Init.OwnAddress1 = 0;
  hi2c1.Init.AddressingMode = I2C_ADDRESSINGMODE_7BIT;
  hi2c1.Init.DualAddressMode = I2C_DUALADDRESS_DISABLE;
  hi2c1.Init.OwnAddress2 = 0;
  hi2c1.Init.GeneralCallMode = I2C_GENERALCALL_DISABLE;
  hi2c1.Init.NoStretchMode = I2C_NOSTRETCH_DISABLE;
  if (HAL_I2C_Init(&hi2c1) != HAL_OK)
  {
    _Error_Handler(__FILE__, __LINE__);
  }

}

/* I2C2 init function */
static void MX_I2C2_Init(void)
{

  hi2c2.Instance = I2C2;
  hi2c2.Init.ClockSpeed = 100000;
  hi2c2.Init.DutyCycle = I2C_DUTYCYCLE_2;
  hi2c2.Init.OwnAddress1 = 0;
  hi2c2.Init.AddressingMode = I2C_ADDRESSINGMODE_7BIT;
  hi2c2.Init.DualAddressMode = I2C_DUALADDRESS_DISABLE;
  hi2c2.Init.OwnAddress2 = 0;
  hi2c2.Init.GeneralCallMode = I2C_GENERALCALL_DISABLE;
  hi2c2.Init.NoStretchMode = I2C_NOSTRETCH_DISABLE;
  if (HAL_I2C_Init(&hi2c2) != HAL_OK)
  {
    _Error_Handler(__FILE__, __LINE__);
  }

}

/* SPI2 init function */
static void MX_SPI2_Init(void)
{

  /* SPI2 parameter configuration*/
  hspi2.Instance = SPI2;
  hspi2.Init.Mode = SPI_MODE_MASTER;
  hspi2.Init.Direction = SPI_DIRECTION_2LINES;
  hspi2.Init.DataSize = SPI_DATASIZE_8BIT;
  hspi2.Init.CLKPolarity = SPI_POLARITY_LOW;
  hspi2.Init.CLKPhase = SPI_PHASE_1EDGE;
  hspi2.Init.NSS = SPI_NSS_SOFT;
  hspi2.Init.BaudRatePrescaler = SPI_BAUDRATEPRESCALER_2;
  hspi2.Init.FirstBit = SPI_FIRSTBIT_MSB;
  hspi2.Init.TIMode = SPI_TIMODE_DISABLE;
  hspi2.Init.CRCCalculation = SPI_CRCCALCULATION_DISABLE;
  hspi2.Init.CRCPolynomial = 10;
  if (HAL_SPI_Init(&hspi2) != HAL_OK)
  {
    _Error_Handler(__FILE__, __LINE__);
  }

}

/* SPI5 init function */
static void MX_SPI5_Init(void)
{

  /* SPI5 parameter configuration*/
  hspi5.Instance = SPI5;
  hspi5.Init.Mode = SPI_MODE_MASTER;
  hspi5.Init.Direction = SPI_DIRECTION_2LINES;
  hspi5.Init.DataSize = SPI_DATASIZE_8BIT;
  hspi5.Init.CLKPolarity = SPI_POLARITY_LOW;
  hspi5.Init.CLKPhase = SPI_PHASE_1EDGE;
  hspi5.Init.NSS = SPI_NSS_SOFT;
  hspi5.Init.BaudRatePrescaler = SPI_BAUDRATEPRESCALER_8;
  hspi5.Init.FirstBit = SPI_FIRSTBIT_MSB;
  hspi5.Init.TIMode = SPI_TIMODE_DISABLE;
  hspi5.Init.CRCCalculation = SPI_CRCCALCULATION_DISABLE;
  hspi5.Init.CRCPolynomial = 10;
  if (HAL_SPI_Init(&hspi5) != HAL_OK)
  {
    _Error_Handler(__FILE__, __LINE__);
  }

}

/* TIM10 init function */
static void MX_TIM10_Init(void)
{

  htim10.Instance = TIM10;
  htim10.Init.Prescaler = 5;
  htim10.Init.CounterMode = TIM_COUNTERMODE_UP;
  htim10.Init.Period = 239;
  htim10.Init.ClockDivision = TIM_CLOCKDIVISION_DIV1;
  if (HAL_TIM_Base_Init(&htim10) != HAL_OK)
  {
    _Error_Handler(__FILE__, __LINE__);
  }

}

/* USART2 init function */
static void MX_USART2_UART_Init(void)
{

  huart2.Instance = USART2;
  huart2.Init.BaudRate = 115200;
  huart2.Init.WordLength = UART_WORDLENGTH_8B;
  huart2.Init.StopBits = UART_STOPBITS_1;
  huart2.Init.Parity = UART_PARITY_NONE;
  huart2.Init.Mode = UART_MODE_TX_RX;
  huart2.Init.HwFlowCtl = UART_HWCONTROL_NONE;
  huart2.Init.OverSampling = UART_OVERSAMPLING_16;
  if (HAL_UART_Init(&huart2) != HAL_OK)
  {
    _Error_Handler(__FILE__, __LINE__);
  }

}

/* USART6 init function */
static void MX_USART6_UART_Init(void)
{

  huart6.Instance = USART6;
  huart6.Init.BaudRate = 115200;
  huart6.Init.WordLength = UART_WORDLENGTH_8B;
  huart6.Init.StopBits = UART_STOPBITS_1;
  huart6.Init.Parity = UART_PARITY_NONE;
  huart6.Init.Mode = UART_MODE_TX_RX;
  huart6.Init.HwFlowCtl = UART_HWCONTROL_NONE;
  huart6.Init.OverSampling = UART_OVERSAMPLING_16;
  if (HAL_UART_Init(&huart6) != HAL_OK)
  {
    _Error_Handler(__FILE__, __LINE__);
  }

}

/* FMC initialization function */
static void MX_FMC_Init(void)
{
  FMC_NORSRAM_TimingTypeDef Timing;
  FMC_SDRAM_TimingTypeDef SdramTiming;

  /** Perform the SRAM1 memory initialization sequence
  */
  hsram1.Instance = FMC_NORSRAM_DEVICE;
  hsram1.Extended = FMC_NORSRAM_EXTENDED_DEVICE;
  /* hsram1.Init */
  hsram1.Init.NSBank = FMC_NORSRAM_BANK1;
  hsram1.Init.DataAddressMux = FMC_DATA_ADDRESS_MUX_DISABLE;
  hsram1.Init.MemoryType = FMC_MEMORY_TYPE_SRAM;
  hsram1.Init.MemoryDataWidth = FMC_NORSRAM_MEM_BUS_WIDTH_8;
  hsram1.Init.BurstAccessMode = FMC_BURST_ACCESS_MODE_DISABLE;
  hsram1.Init.WaitSignalPolarity = FMC_WAIT_SIGNAL_POLARITY_LOW;
  hsram1.Init.WrapMode = FMC_WRAP_MODE_DISABLE;
  hsram1.Init.WaitSignalActive = FMC_WAIT_TIMING_BEFORE_WS;
  hsram1.Init.WriteOperation = FMC_WRITE_OPERATION_DISABLE;
  hsram1.Init.WaitSignal = FMC_WAIT_SIGNAL_DISABLE;
  hsram1.Init.ExtendedMode = FMC_EXTENDED_MODE_DISABLE;
  hsram1.Init.AsynchronousWait = FMC_ASYNCHRONOUS_WAIT_DISABLE;
  hsram1.Init.WriteBurst = FMC_WRITE_BURST_DISABLE;
  hsram1.Init.ContinuousClock = FMC_CONTINUOUS_CLOCK_SYNC_ONLY;
  hsram1.Init.PageSize = FMC_PAGE_SIZE_NONE;
  /* Timing */
  Timing.AddressSetupTime = 0;
  Timing.AddressHoldTime = 15;
  Timing.DataSetupTime = 1;
  Timing.BusTurnAroundDuration = 0;
  Timing.CLKDivision = 16;
  Timing.DataLatency = 17;
  Timing.AccessMode = FMC_ACCESS_MODE_A;
  /* ExtTiming */

  if (HAL_SRAM_Init(&hsram1, &Timing, NULL) != HAL_OK)
  {
    _Error_Handler(__FILE__, __LINE__);
  }

  /** Perform the SRAM2 memory initialization sequence
  */
  hsram2.Instance = FMC_NORSRAM_DEVICE;
  hsram2.Extended = FMC_NORSRAM_EXTENDED_DEVICE;
  /* hsram2.Init */
  hsram2.Init.NSBank = FMC_NORSRAM_BANK2;
  hsram2.Init.DataAddressMux = FMC_DATA_ADDRESS_MUX_DISABLE;
  hsram2.Init.MemoryType = FMC_MEMORY_TYPE_SRAM;
  hsram2.Init.MemoryDataWidth = FMC_NORSRAM_MEM_BUS_WIDTH_8;
  hsram2.Init.BurstAccessMode = FMC_BURST_ACCESS_MODE_DISABLE;
  hsram2.Init.WaitSignalPolarity = FMC_WAIT_SIGNAL_POLARITY_LOW;
  hsram2.Init.WrapMode = FMC_WRAP_MODE_DISABLE;
  hsram2.Init.WaitSignalActive = FMC_WAIT_TIMING_BEFORE_WS;
  hsram2.Init.WriteOperation = FMC_WRITE_OPERATION_DISABLE;
  hsram2.Init.WaitSignal = FMC_WAIT_SIGNAL_DISABLE;
  hsram2.Init.ExtendedMode = FMC_EXTENDED_MODE_DISABLE;
  hsram2.Init.AsynchronousWait = FMC_ASYNCHRONOUS_WAIT_ENABLE;
  hsram2.Init.WriteBurst = FMC_WRITE_BURST_DISABLE;
  hsram2.Init.ContinuousClock = FMC_CONTINUOUS_CLOCK_SYNC_ONLY;
  hsram2.Init.PageSize = FMC_PAGE_SIZE_NONE;
  /* Timing */
  Timing.AddressSetupTime = 0;
  Timing.AddressHoldTime = 15;
  Timing.DataSetupTime = 1;
  Timing.BusTurnAroundDuration = 0;
  Timing.CLKDivision = 16;
  Timing.DataLatency = 17;
  Timing.AccessMode = FMC_ACCESS_MODE_A;
  /* ExtTiming */

  if (HAL_SRAM_Init(&hsram2, &Timing, NULL) != HAL_OK)
  {
    _Error_Handler(__FILE__, __LINE__);
  }

  /** Perform the SRAM3 memory initialization sequence
  */
  hsram3.Instance = FMC_NORSRAM_DEVICE;
  hsram3.Extended = FMC_NORSRAM_EXTENDED_DEVICE;
  /* hsram3.Init */
  hsram3.Init.NSBank = FMC_NORSRAM_BANK3;
  hsram3.Init.DataAddressMux = FMC_DATA_ADDRESS_MUX_DISABLE;
  hsram3.Init.MemoryType = FMC_MEMORY_TYPE_SRAM;
  hsram3.Init.MemoryDataWidth = FMC_NORSRAM_MEM_BUS_WIDTH_8;
  hsram3.Init.BurstAccessMode = FMC_BURST_ACCESS_MODE_DISABLE;
  hsram3.Init.WaitSignalPolarity = FMC_WAIT_SIGNAL_POLARITY_LOW;
  hsram3.Init.WrapMode = FMC_WRAP_MODE_DISABLE;
  hsram3.Init.WaitSignalActive = FMC_WAIT_TIMING_BEFORE_WS;
  hsram3.Init.WriteOperation = FMC_WRITE_OPERATION_DISABLE;
  hsram3.Init.WaitSignal = FMC_WAIT_SIGNAL_DISABLE;
  hsram3.Init.ExtendedMode = FMC_EXTENDED_MODE_DISABLE;
  hsram3.Init.AsynchronousWait = FMC_ASYNCHRONOUS_WAIT_ENABLE;
  hsram3.Init.WriteBurst = FMC_WRITE_BURST_DISABLE;
  hsram3.Init.ContinuousClock = FMC_CONTINUOUS_CLOCK_SYNC_ONLY;
  hsram3.Init.PageSize = FMC_PAGE_SIZE_NONE;
  /* Timing */
  Timing.AddressSetupTime = 0;
  Timing.AddressHoldTime = 15;
  Timing.DataSetupTime = 1;
  Timing.BusTurnAroundDuration = 0;
  Timing.CLKDivision = 16;
  Timing.DataLatency = 17;
  Timing.AccessMode = FMC_ACCESS_MODE_A;
  /* ExtTiming */

  if (HAL_SRAM_Init(&hsram3, &Timing, NULL) != HAL_OK)
  {
    _Error_Handler(__FILE__, __LINE__);
  }

  /** Perform the SRAM4 memory initialization sequence
  */
  hsram4.Instance = FMC_NORSRAM_DEVICE;
  hsram4.Extended = FMC_NORSRAM_EXTENDED_DEVICE;
  /* hsram4.Init */
  hsram4.Init.NSBank = FMC_NORSRAM_BANK4;
  hsram4.Init.DataAddressMux = FMC_DATA_ADDRESS_MUX_DISABLE;
  hsram4.Init.MemoryType = FMC_MEMORY_TYPE_SRAM;
  hsram4.Init.MemoryDataWidth = FMC_NORSRAM_MEM_BUS_WIDTH_8;
  hsram4.Init.BurstAccessMode = FMC_BURST_ACCESS_MODE_DISABLE;
  hsram4.Init.WaitSignalPolarity = FMC_WAIT_SIGNAL_POLARITY_LOW;
  hsram4.Init.WrapMode = FMC_WRAP_MODE_DISABLE;
  hsram4.Init.WaitSignalActive = FMC_WAIT_TIMING_BEFORE_WS;
  hsram4.Init.WriteOperation = FMC_WRITE_OPERATION_DISABLE;
  hsram4.Init.WaitSignal = FMC_WAIT_SIGNAL_DISABLE;
  hsram4.Init.ExtendedMode = FMC_EXTENDED_MODE_DISABLE;
  hsram4.Init.AsynchronousWait = FMC_ASYNCHRONOUS_WAIT_ENABLE;
  hsram4.Init.WriteBurst = FMC_WRITE_BURST_DISABLE;
  hsram4.Init.ContinuousClock = FMC_CONTINUOUS_CLOCK_SYNC_ONLY;
  hsram4.Init.PageSize = FMC_PAGE_SIZE_NONE;
  /* Timing */
  Timing.AddressSetupTime = 0;
  Timing.AddressHoldTime = 15;
  Timing.DataSetupTime = 1;
  Timing.BusTurnAroundDuration = 0;
  Timing.CLKDivision = 16;
  Timing.DataLatency = 17;
  Timing.AccessMode = FMC_ACCESS_MODE_A;
  /* ExtTiming */

  if (HAL_SRAM_Init(&hsram4, &Timing, NULL) != HAL_OK)
  {
    _Error_Handler(__FILE__, __LINE__);
  }

  /** Perform the SDRAM1 memory initialization sequence
  */
  hsdram1.Instance = FMC_SDRAM_DEVICE;
  /* hsdram1.Init */
  hsdram1.Init.SDBank = FMC_SDRAM_BANK1;
  hsdram1.Init.ColumnBitsNumber = FMC_SDRAM_COLUMN_BITS_NUM_9;
  hsdram1.Init.RowBitsNumber = FMC_SDRAM_ROW_BITS_NUM_13;
  hsdram1.Init.MemoryDataWidth = FMC_SDRAM_MEM_BUS_WIDTH_16;
  hsdram1.Init.InternalBankNumber = FMC_SDRAM_INTERN_BANKS_NUM_4;
  hsdram1.Init.CASLatency = FMC_SDRAM_CAS_LATENCY_2;
  hsdram1.Init.WriteProtection = FMC_SDRAM_WRITE_PROTECTION_DISABLE;
  hsdram1.Init.SDClockPeriod = FMC_SDRAM_CLOCK_PERIOD_2;
  hsdram1.Init.ReadBurst = FMC_SDRAM_RBURST_DISABLE;
  hsdram1.Init.ReadPipeDelay = FMC_SDRAM_RPIPE_DELAY_1;
  /* SdramTiming */
  SdramTiming.LoadToActiveDelay = 2;
  SdramTiming.ExitSelfRefreshDelay = 5;
  SdramTiming.SelfRefreshTime = 4;
  SdramTiming.RowCycleDelay = 5;
  SdramTiming.WriteRecoveryTime = 2;
  SdramTiming.RPDelay = 2;
  SdramTiming.RCDDelay = 2;

  if (HAL_SDRAM_Init(&hsdram1, &SdramTiming) != HAL_OK)
  {
    _Error_Handler(__FILE__, __LINE__);
  }

}

/** Configure pins as
        * Analog
        * Input
        * Output
        * EVENT_OUT
        * EXTI
     PC8   ------> SDIO_D0
     PC9   ------> RCC_MCO_2
     PA8   ------> RCC_MCO_1
     PC10   ------> SDIO_D2
     PC11   ------> SDIO_D3
     PC12   ------> SDIO_CK
     PD2   ------> SDIO_CMD
*/
static void MX_GPIO_Init(void)
{

  GPIO_InitTypeDef GPIO_InitStruct;

  /* GPIO Ports Clock Enable */
  __HAL_RCC_GPIOE_CLK_ENABLE();
  __HAL_RCC_GPIOC_CLK_ENABLE();
  __HAL_RCC_GPIOF_CLK_ENABLE();
  __HAL_RCC_GPIOH_CLK_ENABLE();
  __HAL_RCC_GPIOA_CLK_ENABLE();
  __HAL_RCC_GPIOB_CLK_ENABLE();
  __HAL_RCC_GPIOG_CLK_ENABLE();
  __HAL_RCC_GPIOD_CLK_ENABLE();

  /*Configure GPIO pin Output Level */
  HAL_GPIO_WritePin(GPIOC, LED_R_Pin|LED_G_Pin|LED_B_Pin, GPIO_PIN_RESET);

  /*Configure GPIO pin Output Level */
  HAL_GPIO_WritePin(SPI5_CS_GPIO_Port, SPI5_CS_Pin, GPIO_PIN_SET);

  /*Configure GPIO pin Output Level */
  HAL_GPIO_WritePin(SYS_LED_GPIO_Port, SYS_LED_Pin, GPIO_PIN_SET);

  /*Configure GPIO pin Output Level */
  HAL_GPIO_WritePin(GPIOA, LCD_BLK_Pin|LCD_RS_Pin|BEEP_R_Pin|BEEP_L_Pin, GPIO_PIN_RESET);

  /*Configure GPIO pin Output Level */
  HAL_GPIO_WritePin(GPIOA, LCD_CS_Pin|LCD_RST_Pin, GPIO_PIN_SET);

  /*Configure GPIO pin Output Level */
  HAL_GPIO_WritePin(SPI2_CS_GPIO_Port, SPI2_CS_Pin, GPIO_PIN_SET);

  /*Configure GPIO pin Output Level */
  HAL_GPIO_WritePin(GPIOG, FPGA_CONF_Pin|FPGA_RST_Pin|FPGA_CTL_Pin|KEYPAD_OUTA_Pin
                          |KEYPAD_OUTB_Pin, GPIO_PIN_SET);

  /*Configure GPIO pins : LED_R_Pin LED_G_Pin LED_B_Pin */
  GPIO_InitStruct.Pin = LED_R_Pin|LED_G_Pin|LED_B_Pin;
  GPIO_InitStruct.Mode = GPIO_MODE_OUTPUT_PP;
  GPIO_InitStruct.Pull = GPIO_NOPULL;
  GPIO_InitStruct.Speed = GPIO_SPEED_FREQ_LOW;
  HAL_GPIO_Init(GPIOC, &GPIO_InitStruct);

  /*Configure GPIO pin : SPI5_CS_Pin */
  GPIO_InitStruct.Pin = SPI5_CS_Pin;
  GPIO_InitStruct.Mode = GPIO_MODE_OUTPUT_PP;
  GPIO_InitStruct.Pull = GPIO_NOPULL;
  GPIO_InitStruct.Speed = GPIO_SPEED_FREQ_VERY_HIGH;
  HAL_GPIO_Init(SPI5_CS_GPIO_Port, &GPIO_InitStruct);

  /*Configure GPIO pin : KEYBRD_F1_Pin */
  GPIO_InitStruct.Pin = KEYBRD_F1_Pin;
  GPIO_InitStruct.Mode = GPIO_MODE_INPUT;
  GPIO_InitStruct.Pull = GPIO_PULLUP;
  HAL_GPIO_Init(KEYBRD_F1_GPIO_Port, &GPIO_InitStruct);

  /*Configure GPIO pin : SYS_LED_Pin */
  GPIO_InitStruct.Pin = SYS_LED_Pin;
  GPIO_InitStruct.Mode = GPIO_MODE_OUTPUT_PP;
  GPIO_InitStruct.Pull = GPIO_NOPULL;
  GPIO_InitStruct.Speed = GPIO_SPEED_FREQ_VERY_HIGH;
  HAL_GPIO_Init(SYS_LED_GPIO_Port, &GPIO_InitStruct);

  /*Configure GPIO pins : KEYBRD_F2_Pin KEYBRD_F3_Pin SDIO_INS_Pin */
  GPIO_InitStruct.Pin = KEYBRD_F2_Pin|KEYBRD_F3_Pin|SDIO_INS_Pin;
  GPIO_InitStruct.Mode = GPIO_MODE_INPUT;
  GPIO_InitStruct.Pull = GPIO_PULLUP;
  HAL_GPIO_Init(GPIOA, &GPIO_InitStruct);

  /*Configure GPIO pins : LCD_BLK_Pin LCD_CS_Pin LCD_RS_Pin LCD_RST_Pin
                           BEEP_R_Pin BEEP_L_Pin */
  GPIO_InitStruct.Pin = LCD_BLK_Pin|LCD_CS_Pin|LCD_RS_Pin|LCD_RST_Pin
                          |BEEP_R_Pin|BEEP_L_Pin;
  GPIO_InitStruct.Mode = GPIO_MODE_OUTPUT_PP;
  GPIO_InitStruct.Pull = GPIO_NOPULL;
  GPIO_InitStruct.Speed = GPIO_SPEED_FREQ_VERY_HIGH;
  HAL_GPIO_Init(GPIOA, &GPIO_InitStruct);

  /*Configure GPIO pins : KEYBRD_F4_Pin KEYBRD_F5_Pin */
  GPIO_InitStruct.Pin = KEYBRD_F4_Pin|KEYBRD_F5_Pin;
  GPIO_InitStruct.Mode = GPIO_MODE_INPUT;
  GPIO_InitStruct.Pull = GPIO_PULLUP;
  HAL_GPIO_Init(GPIOC, &GPIO_InitStruct);

  /*Configure GPIO pins : KEYBRD_F6_Pin KEYBRD_F7_Pin KEYBRD_F8_Pin KEYPAD_INA_Pin
                           KEYPAD_INB_Pin KEYPAD_INC_Pin KEYPAD_IND_Pin */
  GPIO_InitStruct.Pin = KEYBRD_F6_Pin|KEYBRD_F7_Pin|KEYBRD_F8_Pin|KEYPAD_INA_Pin
                          |KEYPAD_INB_Pin|KEYPAD_INC_Pin|KEYPAD_IND_Pin;
  GPIO_InitStruct.Mode = GPIO_MODE_INPUT;
  GPIO_InitStruct.Pull = GPIO_PULLUP;
  HAL_GPIO_Init(GPIOB, &GPIO_InitStruct);

  /*Configure GPIO pin : SPI2_CS_Pin */
  GPIO_InitStruct.Pin = SPI2_CS_Pin;
  GPIO_InitStruct.Mode = GPIO_MODE_OUTPUT_PP;
  GPIO_InitStruct.Pull = GPIO_NOPULL;
  GPIO_InitStruct.Speed = GPIO_SPEED_FREQ_VERY_HIGH;
  HAL_GPIO_Init(SPI2_CS_GPIO_Port, &GPIO_InitStruct);

  /*Configure GPIO pin : FPGA_CONF_Pin */
  GPIO_InitStruct.Pin = FPGA_CONF_Pin;
  GPIO_InitStruct.Mode = GPIO_MODE_OUTPUT_OD;
  GPIO_InitStruct.Pull = GPIO_NOPULL;
  GPIO_InitStruct.Speed = GPIO_SPEED_FREQ_VERY_HIGH;
  HAL_GPIO_Init(FPGA_CONF_GPIO_Port, &GPIO_InitStruct);

  /*Configure GPIO pins : FPGA_RST_Pin FPGA_CTL_Pin */
  GPIO_InitStruct.Pin = FPGA_RST_Pin|FPGA_CTL_Pin;
  GPIO_InitStruct.Mode = GPIO_MODE_OUTPUT_OD;
  GPIO_InitStruct.Pull = GPIO_PULLUP;
  GPIO_InitStruct.Speed = GPIO_SPEED_FREQ_VERY_HIGH;
  HAL_GPIO_Init(GPIOG, &GPIO_InitStruct);

  /*Configure GPIO pins : PC8 PC10 PC11 PC12 */
  GPIO_InitStruct.Pin = GPIO_PIN_8|GPIO_PIN_10|GPIO_PIN_11|GPIO_PIN_12;
  GPIO_InitStruct.Mode = GPIO_MODE_AF_PP;
  GPIO_InitStruct.Pull = GPIO_NOPULL;
  GPIO_InitStruct.Speed = GPIO_SPEED_FREQ_VERY_HIGH;
  GPIO_InitStruct.Alternate = GPIO_AF12_SDIO;
  HAL_GPIO_Init(GPIOC, &GPIO_InitStruct);

  /*Configure GPIO pin : PC9 */
  GPIO_InitStruct.Pin = GPIO_PIN_9;
  GPIO_InitStruct.Mode = GPIO_MODE_AF_PP;
  GPIO_InitStruct.Pull = GPIO_NOPULL;
  GPIO_InitStruct.Speed = GPIO_SPEED_FREQ_LOW;
  GPIO_InitStruct.Alternate = GPIO_AF0_MCO;
  HAL_GPIO_Init(GPIOC, &GPIO_InitStruct);

  /*Configure GPIO pin : PA8 */
  GPIO_InitStruct.Pin = GPIO_PIN_8;
  GPIO_InitStruct.Mode = GPIO_MODE_AF_PP;
  GPIO_InitStruct.Pull = GPIO_NOPULL;
  GPIO_InitStruct.Speed = GPIO_SPEED_FREQ_LOW;
  GPIO_InitStruct.Alternate = GPIO_AF0_MCO;
  HAL_GPIO_Init(GPIOA, &GPIO_InitStruct);

  /*Configure GPIO pin : PD2 */
  GPIO_InitStruct.Pin = GPIO_PIN_2;
  GPIO_InitStruct.Mode = GPIO_MODE_AF_PP;
  GPIO_InitStruct.Pull = GPIO_NOPULL;
  GPIO_InitStruct.Speed = GPIO_SPEED_FREQ_VERY_HIGH;
  GPIO_InitStruct.Alternate = GPIO_AF12_SDIO;
  HAL_GPIO_Init(GPIOD, &GPIO_InitStruct);

  /*Configure GPIO pin : FPGA_INT_Pin */
  GPIO_InitStruct.Pin = FPGA_INT_Pin;
  GPIO_InitStruct.Mode = GPIO_MODE_IT_RISING;
  GPIO_InitStruct.Pull = GPIO_PULLUP;
  HAL_GPIO_Init(FPGA_INT_GPIO_Port, &GPIO_InitStruct);

  /*Configure GPIO pins : KEYPAD_OUTA_Pin KEYPAD_OUTB_Pin */
  GPIO_InitStruct.Pin = KEYPAD_OUTA_Pin|KEYPAD_OUTB_Pin;
  GPIO_InitStruct.Mode = GPIO_MODE_OUTPUT_PP;
  GPIO_InitStruct.Pull = GPIO_NOPULL;
  GPIO_InitStruct.Speed = GPIO_SPEED_FREQ_VERY_HIGH;
  HAL_GPIO_Init(GPIOG, &GPIO_InitStruct);

  /*Configure GPIO pin : LCDTC_INT_Pin */
  GPIO_InitStruct.Pin = LCDTC_INT_Pin;
  GPIO_InitStruct.Mode = GPIO_MODE_IT_RISING;
  GPIO_InitStruct.Pull = GPIO_PULLUP;
  HAL_GPIO_Init(LCDTC_INT_GPIO_Port, &GPIO_InitStruct);

  /* EXTI interrupt init*/
  HAL_NVIC_SetPriority(EXTI3_IRQn, 0, 0);
  HAL_NVIC_EnableIRQ(EXTI3_IRQn);

  HAL_NVIC_SetPriority(EXTI9_5_IRQn, 0, 0);
  HAL_NVIC_EnableIRQ(EXTI9_5_IRQn);

}

void _Error_Handler(char *file, int line)
{
  while(1)
  {
  }
}

/************************ (C) COPYRIGHT STMicroelectronics *****END OF FILE****/
